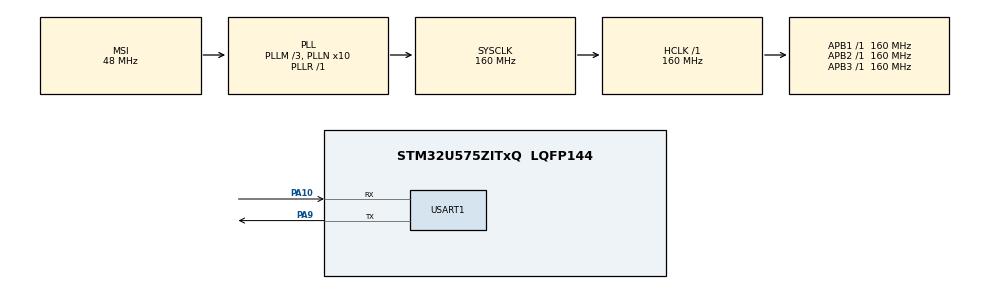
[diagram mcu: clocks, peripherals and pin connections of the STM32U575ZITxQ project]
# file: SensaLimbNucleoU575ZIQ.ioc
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CORTEX_M33_NS.userName=CORTEX_M33
GPDMA1.CIRCULARMODE_GPDMACH1=ENABLE
GPDMA1.DESTINC_GPDMACH1=DMA_DINC_INCREMENTED
GPDMA1.IPHANDLE_GPDMACH1-SIMPLEREQUEST_GPDMACH1=__NULL
GPDMA1.REQUEST_GPDMACH1=GPDMA1_REQUEST_USART1_RX
Mcu.Family=STM32U5
Mcu.Name=STM32U575ZITxQ
Mcu.Package=LQFP144
NVIC.GPDMA1_Channel1_IRQn=true\:0\:0\:false\:false\:true\:false\:true\:true
NVIC.PriorityGroup=NVIC_PRIORITYGROUP_3
NVIC.TIM17_IRQn=true\:7\:0\:false\:false\:true\:false\:true\:true
NVIC.TimeBase=TIM17_IRQn
NVIC.TimeBaseIP=TIM17
NVIC.USART1_IRQn=true\:0\:0\:false\:false\:true\:true\:true\:true
PA10.Mode=Asynchronous
PA10.Signal=USART1_RX
PA13\ (JTMS/SWDIO).Signal=DEBUG_JTMS-SWDIO
PA14\ (JTCK/SWCLK).Signal=DEBUG_JTCK-SWCLK
PA9.Mode=Asynchronous
PA9.Signal=USART1_TX
PB3\ (JTDO/TRACESWO).Signal=DEBUG_JTDO-SWO
PC14-OSC32_IN\ (PC14).Signal=RCC_OSC32_IN
PC15-OSC32_OUT\ (PC15).Signal=RCC_OSC32_OUT
PWR.PowerMode=PWR_SMPS_SUPPLY
ProjectManager.HeapSize=0x800
ProjectManager.StackSize=0x800
ProjectManager.TargetToolchain=STM32CubeIDE
RCC.ADCCLockSelection=RCC_ADCDACCLKSOURCE_PLL2
RCC.ADCFreq_Value=160000000
RCC.AHBFreq_Value=160000000
RCC.APB1Freq_Value=160000000
RCC.APB1TimFreq_Value=160000000
RCC.APB2Freq_Value=160000000
RCC.APB2TimFreq_Value=160000000
RCC.APB3Freq_Value=160000000
RCC.CortexFreq_Value=160000000
RCC.DACCLockSelectionVirtual=RCC_DAC1CLKSOURCE_LSI
RCC.EPOD_VALUE=48000000
RCC.HCLKFreq_Value=160000000
RCC.HSE_VALUE=16000000
RCC.HSI48_VALUE=48000000
RCC.HSI_VALUE=16000000
RCC.LSE_VALUE=32768
RCC.LSIDIV_VALUE=32000
RCC.MSIClockRange=RCC_MSIRANGE_0
RCC.MSI_VALUE=48000000
RCC.PLL1R=1
RCC.PLL2M=3
RCC.PLL2N=20
RCC.PLLM=3
RCC.PLLN=10
RCC.PWR_Regulator_Voltage_Scale=PWR_REGULATOR_VOLTAGE_SCALE1
RCC.SYSCLKFreq_VALUE=160000000
RCC.SYSCLKSource=RCC_SYSCLKSOURCE_PLLCLK
RCC.USBFreq_Value=48000000
RCC.VCOOutputFreq_Value=160000000
STMicroelectronics.X-CUBE-AI.10.2.0.ActivationBufferSizeList=18828
STMicroelectronics.X-CUBE-AI.10.2.0.ActivationBuffers=pool0
STMicroelectronics.X-CUBE-AI.10.2.0.ActivationNames=pool0
STMicroelectronics.X-CUBE-AI.10.2.0.ActivationSizes=AI_NETWORK_DATA_ACTIVATION_1_SIZE
STMicroelectronics.X-CUBE-AI.10.2.0.HeapSize=0x800
STMicroelectronics.X-CUBE-AI.10.2.0.InternalRamActivationBufferMaxSize=AI_NETWORK_DATA_ACTIVATIONS_SIZE
STMicroelectronics.X-CUBE-AI.10.2.0.LatestDirectoryUsed-07a9278990f5f8010873a2d4316044f67b285e8699fffd767027902bf4a55347=C\:\\Users\\Public\\Documents\\Altium\\SensaLimb\\SensaLimbNucleoU575ZIQ
STMicroelectronics.X-CUBE-AI.10.2.0.MaximumNumberOfInputLayer=1
STMicroelectronics.X-CUBE-AI.10.2.0.MaximumNumberOfOutputLayer=1
STMicroelectronics.X-CUBE-AI.10.2.0.MaximumSizeOfInputLayer=1
STMicroelectronics.X-CUBE-AI.10.2.0.MaximumSizeOfOutputLayer=1
STMicroelectronics.X-CUBE-AI.10.2.0.ModelActualCompression-07a9278990f5f8010873a2d4316044f67b285e8699fffd767027902bf4a55347=0.0
STMicroelectronics.X-CUBE-AI.10.2.0.ModelCompression-07a9278990f5f8010873a2d4316044f67b285e8699fffd767027902bf4a55347=None
STMicroelectronics.X-CUBE-AI.10.2.0.ModelFlashOccupation-07a9278990f5f8010873a2d4316044f67b285e8699fffd767027902bf4a55347=118614
STMicroelectronics.X-CUBE-AI.10.2.0.ModelHashList=07a9278990f5f8010873a2d4316044f67b285e8699fffd767027902bf4a55347
STMicroelectronics.X-CUBE-AI.10.2.0.ModelKind-07a9278990f5f8010873a2d4316044f67b285e8699fffd767027902bf4a55347=TFLITE
STMicroelectronics.X-CUBE-AI.10.2.0.ModelMacc-07a9278990f5f8010873a2d4316044f67b285e8699fffd767027902bf4a55347=1855458
STMicroelectronics.X-CUBE-AI.10.2.0.ModelName-07a9278990f5f8010873a2d4316044f67b285e8699fffd767027902bf4a55347=network
STMicroelectronics.X-CUBE-AI.10.2.0.ModelNameList=network
STMicroelectronics.X-CUBE-AI.10.2.0.ModelRamOccupation-07a9278990f5f8010873a2d4316044f67b285e8699fffd767027902bf4a55347=18828
STMicroelectronics.X-CUBE-AI.10.2.0.ModelStructureFile-07a9278990f5f8010873a2d4316044f67b285e8699fffd767027902bf4a55347=model_int8.tflite
STMicroelectronics.X-CUBE-AI.10.2.0.ModelType-07a9278990f5f8010873a2d4316044f67b285e8699fffd767027902bf4a55347=STM32Cube.AI MCU runtime
STMicroelectronics.X-CUBE-AI.10.2.0.ReadyForCodeGeneration=true
STMicroelectronics.X-CUBE-AI.10.2.0.StackSize=0x800
STMicroelectronics.X-CUBE-AI.10.2.0.WorkingBufferStartAddrList=0xFFFFFFFF
STMicroelectronics.X-CUBE-AI.10.2.0.XAaCUBEAaAICcArtificialOoIntelligenceJjCore=true
STMicroelectronics.X-CUBE-AI.10.2.0.copyWeightToRam-07a9278990f5f8010873a2d4316044f67b285e8699fffd767027902bf4a55347=false
STMicroelectronics.X-CUBE-AI.10.2.0.customLayerConfigEnabled-07a9278990f5f8010873a2d4316044f67b285e8699fffd767027902bf4a55347=false
STMicroelectronics.X-CUBE-AI.10.2.0.noOnnxIoTranspose-07a9278990f5f8010873a2d4316044f67b285e8699fffd767027902bf4a55347=false
STMicroelectronics.X-CUBE-AI.10.2.0.useInputAllocation-07a9278990f5f8010873a2d4316044f67b285e8699fffd767027902bf4a55347=true
STMicroelectronics.X-CUBE-AI.10.2.0.useOutputAllocation-07a9278990f5f8010873a2d4316044f67b285e8699fffd767027902bf4a55347=true
USART1.VirtualMode-Asynchronous=VM_ASYNC
VP_GPDMA1_VS_GPDMACH1.Mode=SIMPLEREQUEST_GPDMACH1
VP_ICACHE_VS_ENABLE_ICACHE_MEMORY.Mode=Memoryregions
VP_ICACHE_VS_ICACHE.Mode=DirectMappedCache
VP_LPBAMQUEUE_VS_QUEUE.Mode=QUEUEMODE
VP_LPBAM_VS_SIG1.Mode=SmartRun
VP_LPBAM_VS_SIG4.Mode=LPDMA1
VP_MEMORYMAP_VS_MEMORYMAP.Mode=CurAppReg
VP_PWR_VS_DBSignals.Mode=DisableDeadBatterySignals
VP_PWR_VS_LPOM.Mode=PowerOptimisation
VP_PWR_VS_SECSignals.Mode=Security/Privilege
VP_STMicroelectronics.X-CUBE-AI_VS_ArtificialOoIntelligenceJjXAaCUBEAaAI_10.2.0.Mode=ArtificialOoIntelligenceJjXAaCUBEAaAI
VP_SYS_VS_tim17.Mode=TIM17
board=NUCLEO-U575ZI-Q

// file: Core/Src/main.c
/* USER CODE BEGIN Header */
/**
  ******************************************************************************
  * @file           : main.c
  * @brief          : Main program body
  ******************************************************************************
  * @attention
  *
  * Copyright (c) 2026 STMicroelectronics.
  * All rights reserved.
  *
  * This software is licensed under terms that can be found in the LICENSE file
  * in the root directory of this software component.
  * If no LICENSE file comes with this software, it is provided AS-IS.
  *
  ******************************************************************************
  */
/* USER CODE END Header */
#include "main.h"
#include "gpdma.h"
#include "icache.h"
#include "usart.h"
#include "gpio.h"

/* USER CODE BEGIN Includes */
#include "ad7606.h"
#include "control_loop.h"

/* USER CODE END Includes */

void SystemClock_Config(void);
static void SystemPower_Config(void);

int main(void)
{

  /* MCU Configuration--------------------------------------------------------*/

  /* Reset of all peripherals, Initializes the Flash interface and the Systick. */
  HAL_Init();

  /* Configure the System Power */
  SystemPower_Config();

  /* Configure the system clock */
  SystemClock_Config();

  /* Initialize all configured peripherals */
  MX_GPIO_Init();
  MX_GPDMA1_Init();
  MX_ICACHE_Init();
  MX_USART1_UART_Init();
  /* USER CODE BEGIN 2 */
#if AD7606_FORCE_FAKE
  for (int i = 0; i < 2; i++) {
    HAL_GPIO_TogglePin(LD1_GPIO_Port, LD1_Pin);
    HAL_Delay(1000);
    HAL_GPIO_TogglePin(LD1_GPIO_Port, LD1_Pin);
    HAL_Delay(1000);
  }
#else
  for (int i = 0; i < 2; i++) {
    HAL_GPIO_TogglePin(LD2_GPIO_Port, LD2_Pin);
    HAL_Delay(2500);
    HAL_GPIO_TogglePin(LD2_GPIO_Port, LD2_Pin);
    HAL_Delay(2500);
  }
#endif
  control_init();

  /* USER CODE END 2 */

  /* Infinite loop */
  while (1)
  {

    /* USER CODE BEGIN 3 */
    control_tick();
  }
  /* USER CODE END 3 */
}

void SystemClock_Config(void)
{
  RCC_OscInitTypeDef RCC_OscInitStruct = {0};
  RCC_ClkInitTypeDef RCC_ClkInitStruct = {0};

  /** Configure the main internal regulator output voltage
  */
  if (HAL_PWREx_ControlVoltageScaling(PWR_REGULATOR_VOLTAGE_SCALE1) != HAL_OK)
  {
    Error_Handler();
  }

  /** Initializes the CPU, AHB and APB buses clocks
  */
  RCC_OscInitStruct.OscillatorType = RCC_OSCILLATORTYPE_MSI;
  RCC_OscInitStruct.MSIState = RCC_MSI_ON;
  RCC_OscInitStruct.MSICalibrationValue = RCC_MSICALIBRATION_DEFAULT;
  RCC_OscInitStruct.MSIClockRange = RCC_MSIRANGE_0;
  RCC_OscInitStruct.PLL.PLLState = RCC_PLL_ON;
  RCC_OscInitStruct.PLL.PLLSource = RCC_PLLSOURCE_MSI;
  RCC_OscInitStruct.PLL.PLLMBOOST = RCC_PLLMBOOST_DIV4;
  RCC_OscInitStruct.PLL.PLLM = 3;
  RCC_OscInitStruct.PLL.PLLN = 10;
  RCC_OscInitStruct.PLL.PLLP = 2;
  RCC_OscInitStruct.PLL.PLLQ = 2;
  RCC_OscInitStruct.PLL.PLLR = 1;
  RCC_OscInitStruct.PLL.PLLRGE = RCC_PLLVCIRANGE_1;
  RCC_OscInitStruct.PLL.PLLFRACN = 0;
  if (HAL_RCC_OscConfig(&RCC_OscInitStruct) != HAL_OK)
  {
    Error_Handler();
  }

  /** Initializes the CPU, AHB and APB buses clocks
  */
  RCC_ClkInitStruct.ClockType = RCC_CLOCKTYPE_HCLK|RCC_CLOCKTYPE_SYSCLK
                              |RCC_CLOCKTYPE_PCLK1|RCC_CLOCKTYPE_PCLK2
                              |RCC_CLOCKTYPE_PCLK3;
  RCC_ClkInitStruct.SYSCLKSource = RCC_SYSCLKSOURCE_PLLCLK;
  RCC_ClkInitStruct.AHBCLKDivider = RCC_SYSCLK_DIV1;
  RCC_ClkInitStruct.APB1CLKDivider = RCC_HCLK_DIV1;
  RCC_ClkInitStruct.APB2CLKDivider = RCC_HCLK_DIV1;
  RCC_ClkInitStruct.APB3CLKDivider = RCC_HCLK_DIV1;

  if (HAL_RCC_ClockConfig(&RCC_ClkInitStruct, FLASH_LATENCY_4) != HAL_OK)
  {
    Error_Handler();
  }
}

/**
  * @brief Power Configuration
  * @retval None
  */
static void SystemPower_Config(void)
{

  /*
   * Disable the internal Pull-Up in Dead Battery pins of UCPD peripheral
   */
  HAL_PWREx_DisableUCPDDeadBattery();

  /*
   * Switch to SMPS regulator instead of LDO
   */
  if (HAL_PWREx_ConfigSupply(PWR_SMPS_SUPPLY) != HAL_OK)
  {
    Error_Handler();
  }
/* USER CODE BEGIN PWR */
  HAL_PWREx_EnableVddIO2();
/* USER CODE END PWR */
}

void HAL_TIM_PeriodElapsedCallback(TIM_HandleTypeDef *htim)
{
  /* USER CODE BEGIN Callback 0 */
  if (htim->Instance == TIM17) {
    control_on_sample_tick_isr();
  }
  /* USER CODE END Callback 0 */
  if (htim->Instance == TIM17)
  {
    HAL_IncTick();
  }
}

void Error_Handler(void)
{
  __disable_irq();
  while (1)
  {
  }
}
